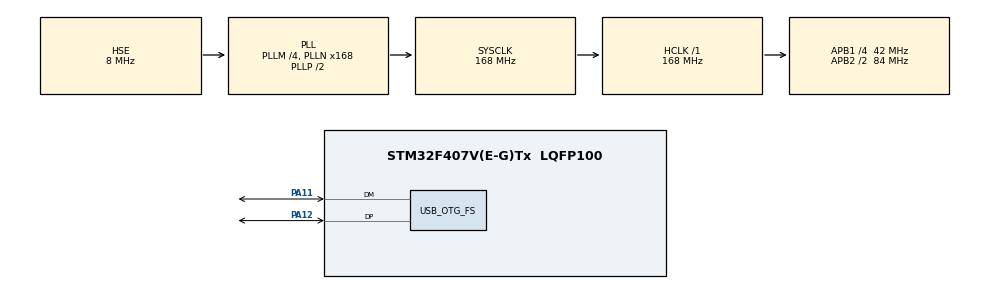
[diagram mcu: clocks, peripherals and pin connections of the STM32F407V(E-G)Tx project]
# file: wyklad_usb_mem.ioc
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Dma.MEMTOMEM.0.Direction=DMA_MEMORY_TO_MEMORY
Dma.MEMTOMEM.0.FIFOMode=DMA_FIFOMODE_ENABLE
Dma.MEMTOMEM.0.FIFOThreshold=DMA_FIFO_THRESHOLD_FULL
Dma.MEMTOMEM.0.Instance=DMA2_Stream0
Dma.MEMTOMEM.0.MemBurst=DMA_MBURST_SINGLE
Dma.MEMTOMEM.0.MemDataAlignment=DMA_MDATAALIGN_BYTE
Dma.MEMTOMEM.0.MemInc=DMA_MINC_ENABLE
Dma.MEMTOMEM.0.Mode=DMA_NORMAL
Dma.MEMTOMEM.0.PeriphBurst=DMA_PBURST_SINGLE
Dma.MEMTOMEM.0.PeriphDataAlignment=DMA_PDATAALIGN_BYTE
Dma.MEMTOMEM.0.PeriphInc=DMA_PINC_ENABLE
Dma.MEMTOMEM.0.Priority=DMA_PRIORITY_LOW
Dma.Request0=MEMTOMEM
Mcu.Family=STM32F4
Mcu.Name=STM32F407V(E-G)Tx
Mcu.Package=LQFP100
NVIC.OTG_FS_IRQn=true\:0\:0\:false\:false\:true\:false\:true\:true
NVIC.PriorityGroup=NVIC_PRIORITYGROUP_0
PA11.Mode=Device_Only
PA11.Signal=USB_OTG_FS_DM
PA12.Mode=Device_Only
PA12.Signal=USB_OTG_FS_DP
PH0-OSC_IN.Mode=HSE-External-Oscillator
PH0-OSC_IN.Signal=RCC_OSC_IN
PH1-OSC_OUT.Mode=HSE-External-Oscillator
PH1-OSC_OUT.Signal=RCC_OSC_OUT
ProjectManager.HeapSize=0x200
ProjectManager.StackSize=0x400
ProjectManager.TargetToolchain=STM32CubeIDE
RCC.48MHZClocksFreq_Value=48000000
RCC.AHBFreq_Value=168000000
RCC.APB1CLKDivider=RCC_HCLK_DIV4
RCC.APB1Freq_Value=42000000
RCC.APB1TimFreq_Value=84000000
RCC.APB2CLKDivider=RCC_HCLK_DIV2
RCC.APB2Freq_Value=84000000
RCC.APB2TimFreq_Value=168000000
RCC.CortexFreq_Value=168000000
RCC.HCLKFreq_Value=168000000
RCC.HSE_VALUE=8000000
RCC.HSI_VALUE=16000000
RCC.LSE_VALUE=32768
RCC.PLLM=4
RCC.PLLN=168
RCC.PLLQ=7
RCC.PLLSourceVirtual=RCC_PLLSOURCE_HSE
RCC.SYSCLKFreq_VALUE=168000000
RCC.SYSCLKSource=RCC_SYSCLKSOURCE_PLLCLK
RCC.VCOOutputFreq_Value=336000000
USB_DEVICE.CLASS_NAME_FS=CDC
USB_DEVICE.VirtualMode-CDC_FS=Cdc
USB_DEVICE.VirtualModeFS=Cdc_FS
USB_OTG_FS.VirtualMode=Device_Only
VP_USB_DEVICE_VS_USB_DEVICE_CDC_FS.Mode=CDC_FS
board=STM32F407G-DISC1

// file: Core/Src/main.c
/* USER CODE BEGIN Header */
/**
  ******************************************************************************
  * @file           : main.c
  * @brief          : Main program body
  ******************************************************************************
  * @attention
  *
  * Copyright (c) 2024 STMicroelectronics.
  * All rights reserved.
  *
  * This software is licensed under terms that can be found in the LICENSE file
  * in the root directory of this software component.
  * If no LICENSE file comes with this software, it is provided AS-IS.
  *
  ******************************************************************************
  */
/* USER CODE END Header */
#include "main.h"
#include "usb_device.h"

/* USER CODE BEGIN Includes */
#include "string.h"
#include "stdio.h"
uint8_t DataToSend[40];
uint8_t MessageLenght,MessageCounter=0;
uint8_t indx=1;
uint32_t start_counter;
uint32_t stop_counter;
uint32_t delta_counter;
float comp_time_us=0.0f;

__attribute__ ((section(".TxBuff"), used)) uint8_t TxBuffer[1024];
__attribute__ ((section(".RxBuff"), used)) uint8_t RxBuffer[1024];

#define  ARM_CM_DEMCR      (*(uint32_t *)0xE000EDFC)
#define  ARM_CM_DWT_CTRL   (*(uint32_t *)0xE0001000)
#define  ARM_CM_DWT_CYCCNT (*(uint32_t *)0xE0001004)

#define CPU_SPEED 168.0f
/* USER CODE END Includes */

DMA_HandleTypeDef hdma_memtomem_dma2_stream0;

void SystemClock_Config(void);
static void MX_GPIO_Init(void);
static void MX_DMA_Init(void);

int main(void)
{

  /* MCU Configuration--------------------------------------------------------*/

  /* Reset of all peripherals, Initializes the Flash interface and the Systick. */
  HAL_Init();

  /* Configure the system clock */
  SystemClock_Config();

  /* Initialize all configured peripherals */
  MX_GPIO_Init();
  MX_DMA_Init();
  MX_USB_DEVICE_Init();
  /* USER CODE BEGIN 2 */
  if (ARM_CM_DWT_CTRL != 0) {        // See if DWT is available
      ARM_CM_DEMCR      |= 1 << 24;  // Set bit 24
      ARM_CM_DWT_CYCCNT  = 0;
      ARM_CM_DWT_CTRL   |= 1 << 0;   // Set bit 0
  }
  /* USER CODE END 2 */

  /* Infinite loop */
  while (1)
  {

    /* USER CODE BEGIN 3 */
	  start_counter = ARM_CM_DWT_CYCCNT;

	  memset(TxBuffer,indx,1024);

	  //HAL_DMA_Start(&hdma_memtomem_dma2_stream0, TxBuffer, RxBuffer, 1024);
	  memcpy(RxBuffer,TxBuffer,1024);

	  //HAL_DMA_Abort(&hdma_memtomem_dma2_stream0);

	  stop_counter  = ARM_CM_DWT_CYCCNT;
	  delta_counter = stop_counter - start_counter;
	  comp_time_us = delta_counter/CPU_SPEED;

	  indx++;

	  ++MessageCounter;
	  MessageLenght = sprintf(DataToSend, "Wiadomosc nr. %d\n", MessageCounter);

	  CDC_Transmit_FS(DataToSend,MessageLenght);

	  HAL_Delay(1000);

  }
  /* USER CODE END 3 */
}

void SystemClock_Config(void)
{
  RCC_OscInitTypeDef RCC_OscInitStruct = {0};
  RCC_ClkInitTypeDef RCC_ClkInitStruct = {0};

  /** Configure the main internal regulator output voltage
  */
  __HAL_RCC_PWR_CLK_ENABLE();
  __HAL_PWR_VOLTAGESCALING_CONFIG(PWR_REGULATOR_VOLTAGE_SCALE1);

  /** Initializes the RCC Oscillators according to the specified parameters
  * in the RCC_OscInitTypeDef structure.
  */
  RCC_OscInitStruct.OscillatorType = RCC_OSCILLATORTYPE_HSE;
  RCC_OscInitStruct.HSEState = RCC_HSE_ON;
  RCC_OscInitStruct.PLL.PLLState = RCC_PLL_ON;
  RCC_OscInitStruct.PLL.PLLSource = RCC_PLLSOURCE_HSE;
  RCC_OscInitStruct.PLL.PLLM = 4;
  RCC_OscInitStruct.PLL.PLLN = 168;
  RCC_OscInitStruct.PLL.PLLP = RCC_PLLP_DIV2;
  RCC_OscInitStruct.PLL.PLLQ = 7;
  if (HAL_RCC_OscConfig(&RCC_OscInitStruct) != HAL_OK)
  {
    Error_Handler();
  }

  /** Initializes the CPU, AHB and APB buses clocks
  */
  RCC_ClkInitStruct.ClockType = RCC_CLOCKTYPE_HCLK|RCC_CLOCKTYPE_SYSCLK
                              |RCC_CLOCKTYPE_PCLK1|RCC_CLOCKTYPE_PCLK2;
  RCC_ClkInitStruct.SYSCLKSource = RCC_SYSCLKSOURCE_PLLCLK;
  RCC_ClkInitStruct.AHBCLKDivider = RCC_SYSCLK_DIV1;
  RCC_ClkInitStruct.APB1CLKDivider = RCC_HCLK_DIV4;
  RCC_ClkInitStruct.APB2CLKDivider = RCC_HCLK_DIV2;

  if (HAL_RCC_ClockConfig(&RCC_ClkInitStruct, FLASH_LATENCY_5) != HAL_OK)
  {
    Error_Handler();
  }
}

static void MX_DMA_Init(void)
{

  /* DMA controller clock enable */
  __HAL_RCC_DMA2_CLK_ENABLE();

  /* Configure DMA request hdma_memtomem_dma2_stream0 on DMA2_Stream0 */
  hdma_memtomem_dma2_stream0.Instance = DMA2_Stream0;
  hdma_memtomem_dma2_stream0.Init.Channel = DMA_CHANNEL_0;
  hdma_memtomem_dma2_stream0.Init.Direction = DMA_MEMORY_TO_MEMORY;
  hdma_memtomem_dma2_stream0.Init.PeriphInc = DMA_PINC_ENABLE;
  hdma_memtomem_dma2_stream0.Init.MemInc = DMA_MINC_ENABLE;
  hdma_memtomem_dma2_stream0.Init.PeriphDataAlignment = DMA_PDATAALIGN_BYTE;
  hdma_memtomem_dma2_stream0.Init.MemDataAlignment = DMA_MDATAALIGN_BYTE;
  hdma_memtomem_dma2_stream0.Init.Mode = DMA_NORMAL;
  hdma_memtomem_dma2_stream0.Init.Priority = DMA_PRIORITY_LOW;
  hdma_memtomem_dma2_stream0.Init.FIFOMode = DMA_FIFOMODE_ENABLE;
  hdma_memtomem_dma2_stream0.Init.FIFOThreshold = DMA_FIFO_THRESHOLD_FULL;
  hdma_memtomem_dma2_stream0.Init.MemBurst = DMA_MBURST_SINGLE;
  hdma_memtomem_dma2_stream0.Init.PeriphBurst = DMA_PBURST_SINGLE;
  if (HAL_DMA_Init(&hdma_memtomem_dma2_stream0) != HAL_OK)
  {
    Error_Handler( );
  }

}

static void MX_GPIO_Init(void)
{

  /* GPIO Ports Clock Enable */
  __HAL_RCC_GPIOH_CLK_ENABLE();
  __HAL_RCC_GPIOA_CLK_ENABLE();

}

void Error_Handler(void)
{
  __disable_irq();
  while (1)
  {
  }
}
